AUTOSAR XML (schema 00049)
package /MICROSAR/Dem_swc/DataTypes
  26 x impl type:
    Dem_EventIdType: range raw 1..65535, implementation-data-type=uint16
    Dem_RatioIdType: range raw 1..65535, implementation-data-type=uint16
    Dem_DTCStatusMaskType: range raw 0..255, implementation-data-type=uint8
    Dem_OperationCycleIdType: range raw 0..255, implementation-data-type=uint8
    Dem_DTCGroupType: range raw 0..16777215, implementation-data-type=uint32
    Dem_DebouncingStateType:
      compu {mask 1: 1=DEM_TEMPORARILY_DEFECTIVE (Bit 0: Temporarily Defective (corresponds to 0 < FDC < 127)), mask 2: 2=DEM_FINALLY_DEFECTIVE (Bit 1: Finally Defective (corresponds to FDC = 127)), mask 4: 4=DEM_TEMPORARILY_HEALED (Bit 2: Temporarily healed (corresponds to -128 < FDC < 0)), mask 8: 8=DEM_TEST_COMPLETE (Bit 3: Test complete (corresponds to FDC = -128 or FDC = 127)), mask 16: 16=DEM_DTR_UPDATE (Bit 4: DTR Update (= Test complete && Debouncing complete && enable conditions / storage conditions fulfilled))}
      range raw 0..255
      implementation-data-type=uint8
    Dem_UdsStatusByteType:
      compu {mask 1: 1=DEM_UDS_STATUS_TF (bit 0: TestFailed), mask 2: 2=DEM_UDS_STATUS_TFTOC (bit 1: TestFailedThisOperationCycle), mask 4: 4=DEM_UDS_STATUS_PDTC (bit 2: PendingDTC), mask 8: 8=DEM_UDS_STATUS_CDTC (bit 3: ConfirmedDTC), mask 16: 16=DEM_UDS_STATUS_TNCSLC (bit 4: TestNotCompletedSinceLastClear), mask 32: 32=DEM_UDS_STATUS_TFSLC (bit 5: TestFailedSinceLastClear), mask 64: 64=DEM_UDS_STATUS_TNCTOC (bit 6: TestNotCompletedThisOperationCycle), mask 128: 128=DEM_UDS_STATUS_WIR (bit 7: WarningIndicatorRequested)}
      range raw 0..255
      implementation-data-type=uint8
    Dem_DTCSeverityType:
      compu {mask 255: 0=DEM_SEVERITY_NO_SEVERITY (DTC_NO_SEVERITY) (No severity information available), mask 31: 1=DEM_SEVERITY_WWHOBD_CLASS_NO_CLASS (DTC_CLASS) (No class information), mask 31: 2=DEM_SEVERITY_WWHOBD_CLASS_A (DTC_CLASS) (WWH-OBD Class A), mask 31: 4=DEM_SEVERITY_WWHOBD_CLASS_B1 (DTC_CLASS) (WWH-OBD Class B1), mask 31: 8=DEM_SEVERITY_WWHOBD_CLASS_B2 (DTC_CLASS) (WWH-OBD Class B2), mask 31: 16=DEM_SEVERITY_WWHOBD_CLASS_C (DTC_CLASS) (WWH-OBD Class C), mask 224: 32=DEM_SEVERITY_MAINTENANCE_ONLY (DTC_SEVERITY) (Maintenance required), mask 224: 64=DEM_SEVERITY_CHECK_AT_NEXT_HALT (DTC_SEVERITY) (Check at next halt), mask 224: 128=DEM_SEVERITY_CHECK_IMMEDIATELY (DTC_SEVERITY) (Check immediately)}
      range raw 0..255
      implementation-data-type=uint8
    Dem_MonitorStatusType: compu {mask 1: 1=DEM_MONITOR_STATUS_TF (bit 0: TestFailed), mask 2: 2=DEM_MONITOR_STATUS_TNCTOC (bit 1: TestNotCompletedThisOperationCycle)}, range raw 0..255, implementation-data-type=uint8
    Dem_EventStatusType:
      compu {0=DEM_EVENT_STATUS_PASSED, 1=DEM_EVENT_STATUS_FAILED, 2=DEM_EVENT_STATUS_PREPASSED, 3=DEM_EVENT_STATUS_PREFAILED, 4=DEM_EVENT_STATUS_FDC_THRESHOLD_REACHED, 5=DEM_EVENT_STATUS_PASSED_CONDITIONS_NOT_FULFILLED, 6=DEM_EVENT_STATUS_FAILED_CONDITIONS_NOT_FULFILLED, 7=DEM_EVENT_STATUS_PREPASSED_CONDITIONS_NOT_FULFILLED, 8=DEM_EVENT_STATUS_PREFAILED_CONDITIONS_NOT_FULFILLED}
      range raw 0..255
      implementation-data-type=uint8
    Dem_DTCKindType: compu {1=DEM_DTC_KIND_ALL_DTCS, 2=DEM_DTC_KIND_EMISSION_REL_DTCS}, range raw 0..255, implementation-data-type=uint8
    Dem_IumprDenomCondStatusType: compu {0=DEM_IUMPR_DEN_STATUS_NOT_REACHED, 1=DEM_IUMPR_DEN_STATUS_REACHED, 2=DEM_IUMPR_DEN_STATUS_INHIBITED}, range raw 0..255, implementation-data-type=uint8
    Dem_DebounceResetStatusType: compu {0=DEM_DEBOUNCE_STATUS_FREEZE, 1=DEM_DEBOUNCE_STATUS_RESET}, range raw 0..255, implementation-data-type=uint8
    Dem_DTRControlType: compu {0=DEM_DTR_CTL_NORMAL, 1=DEM_DTR_CTL_NO_MAX, 2=DEM_DTR_CTL_NO_MIN, 3=DEM_DTR_CTL_RESET, 4=DEM_DTR_CTL_INVISIBLE}, range raw 0..255, implementation-data-type=uint8
    Dem_IumprReadinessGroupType:
      compu {0=DEM_IUMPR_BOOSTPRS, 1=DEM_IUMPR_CAT1, 2=DEM_IUMPR_CAT2, 3=DEM_IUMPR_EGR, 4=DEM_IUMPR_EGSENSOR, 5=DEM_IUMPR_EVAP, 6=DEM_IUMPR_NMHCCAT, 7=DEM_IUMPR_NOXADSORB, 8=DEM_IUMPR_NOXCAT, 9=DEM_IUMPR_OXS1, 10=DEM_IUMPR_OXS2, 11=DEM_IUMPR_PMFILTER, 12=DEM_IUMPR_PRIVATE, 13=DEM_IUMPR_SAIR, 14=DEM_IUMPR_SECOXS1, 15=DEM_IUMPR_SECOXS2, 16=DEM_IUMPR_FLSYS, 17=DEM_IUMPR_AFRI1, 18=DEM_IUMPR_AFRI2, 19=DEM_IUMPR_PF1, 20=DEM_IUMPR_PF2, 255=DEM_IUMPR_ALLGROUPS}
      range raw 0..255
      implementation-data-type=uint8
    Dem_IumprDenomCondIdType: compu {1=DEM_IUMPR_GENERAL_DENOMINATOR, 2=DEM_IUMPR_DEN_COND_COLDSTART, 3=DEM_IUMPR_DEN_COND_EVAP, 4=DEM_IUMPR_DEN_COND_500MI, 5=DEM_IUMPR_GENERAL_INDIVIDUAL_DENOMINATOR, 6=DEM_IUMPR_GENERAL_OBDCOND, 7=DEM_IUMPR_DEN_COND_INDEPENDENT}, range raw 0..255, implementation-data-type=uint8
    Dem_InitMonitorReasonType: compu {1=DEM_INIT_MONITOR_CLEAR, 2=DEM_INIT_MONITOR_RESTART, 3=DEM_INIT_MONITOR_REENABLED, 4=DEM_INIT_MONITOR_STORAGE_REENABLED}, range raw 1..4, implementation-data-type=uint8
    Dem_OperationCycleStateType: compu {0=DEM_CYCLE_STATE_START, 1=DEM_CYCLE_STATE_END}, range raw 0..1, implementation-data-type=uint8
    Dem_IndicatorStatusType: compu {0=DEM_INDICATOR_OFF, 1=DEM_INDICATOR_CONTINUOUS, 2=DEM_INDICATOR_BLINKING, 3=DEM_INDICATOR_BLINK_CONT, 4=DEM_INDICATOR_SLOW_FLASH, 5=DEM_INDICATOR_FAST_FLASH, 6=DEM_INDICATOR_ON_DEMAND, 7=DEM_INDICATOR_SHORT}, range raw 0..7, implementation-data-type=uint8
    Dem_DTCOriginType: compu {1=DEM_DTC_ORIGIN_PRIMARY_MEMORY, 2=DEM_DTC_ORIGIN_MIRROR_MEMORY, 3=DEM_DTC_ORIGIN_PERMANENT_MEMORY, 4=DEM_DTC_ORIGIN_OBD_RELEVANT_MEMORY, 256=DEM_DTC_ORIGIN_SECONDARY_MEMORY}, range raw 1..511, implementation-data-type=uint16
    Dem_BufferLengthType: range raw 1..65535, implementation-data-type=uint16
    Dcm_NegativeResponseCodeType: range raw 1..255, implementation-data-type=uint8
    Dem_DTCFormatType: compu {0=DEM_DTC_FORMAT_OBD, 1=DEM_DTC_FORMAT_UDS, 2=DEM_DTC_FORMAT_J1939, 3=DEM_DTC_FORMAT_OBD_3BYTE}, range raw 0..3, implementation-data-type=uint8
    Dem_MaxDataValueType: category=ARRAY, sw-calibration-access=READ-ONLY
      element Dem_MaxDataValueTypeElement: array-size=6, array-size-semantics=FIXED-SIZE, implementation-data-type=uint8
    DataPrimitiveType_uint16: implementation-data-type=uint16
    DataArrayType_uint8_6: category=ARRAY, sw-calibration-access=READ-ONLY
      element DataArrayType_uint8_6Element: array-size=6, array-size-semantics=FIXED-SIZE, implementation-data-type=uint8
package /MICROSAR/Dem_swc/Interfaces
  12 x client server interface, all with is-service=true, service-kind=DIAGNOSTIC-EVENT-MANAGER:
    DemServices
      operation GetPostRunRequested: possible-error=DemServices/E_NOT_OK
        arg IsRequested: type=boolean, direction=OUT
      operation GetDTCStatusAvailabilityMask: possible-error=DemServices/E_NOT_OK
        arg ClientId: type=uint8, direction=IN
        arg DTCStatusMask: type=uint8, direction=OUT
      error E_NOT_OK: error-code=1
    EvMemOverflowIndication
      operation GetEventMemoryOverflow: possible-error=EvMemOverflowIndication/E_NOT_OK
        arg OverflowIndication: type=boolean, direction=OUT
      operation GetNumberOfEventMemoryEntries: possible-error=EvMemOverflowIndication/E_NOT_OK
        arg NumberOfEventMemoryEntries: type=uint8, direction=OUT
      error E_NOT_OK: error-code=1
    GeneralDiagnosticInfo
      11 x operation:
        GetEventStatus: possible-error=GeneralDiagnosticInfo/E_NOT_OK
          arg EventId: type=Dem_EventIdType, direction=IN
          arg UDSStatusByte: type=Dem_UdsStatusByteType, direction=OUT
        GetEventFailed: possible-error=GeneralDiagnosticInfo/E_NOT_OK
          arg EventId: type=Dem_EventIdType, direction=IN
          arg EventFailed: type=boolean, direction=OUT
        GetEventTested: possible-error=GeneralDiagnosticInfo/E_NOT_OK
          arg EventId: type=Dem_EventIdType, direction=IN
          arg EventTested: type=boolean, direction=OUT
        GetDTCOfEvent: possible-error=[GeneralDiagnosticInfo/E_NOT_OK, GeneralDiagnosticInfo/DEM_E_NO_DTC_AVAILABLE]
          arg EventId: type=Dem_EventIdType, direction=IN
          arg DTCFormat: type=Dem_DTCFormatType, direction=IN
          arg DTCOfEvent: type=uint32, direction=OUT
        GetFaultDetectionCounter: possible-error=[GeneralDiagnosticInfo/E_NOT_OK, GeneralDiagnosticInfo/DEM_E_NO_FDC_AVAILABLE]
          arg EventId: type=Dem_EventIdType, direction=IN
          arg FaultDetectionCounter: type=sint8, direction=OUT
        GetEventEnableCondition: possible-error=GeneralDiagnosticInfo/E_NOT_OK
          arg EventId: type=Dem_EventIdType, direction=IN
          arg ConditionFullfilled: type=boolean, direction=OUT
        GetDebouncingOfEvent: possible-error=GeneralDiagnosticInfo/E_NOT_OK
          arg EventId: type=Dem_EventIdType, direction=IN
          arg DebouncingState: type=Dem_DebouncingStateType, direction=OUT
        GetEventUdsStatus: possible-error=GeneralDiagnosticInfo/E_NOT_OK
          arg EventId: type=Dem_EventIdType, direction=IN
          arg UDSStatusByte: type=Dem_UdsStatusByteType, direction=OUT
        GetEventFreezeFrameDataEx: possible-error=[GeneralDiagnosticInfo/E_NOT_OK, GeneralDiagnosticInfo/DEM_BUFFER_TOO_SMALL, GeneralDiagnosticInfo/DEM_NO_SUCH_ELEMENT]
          5 x arg:
            EventId: type=Dem_EventIdType, direction=IN
            RecordNumber: type=uint8, direction=IN
            DataId: type=uint16, direction=IN
            DestBuffer: type=Dem_MaxDataValueType, direction=OUT
            BufSize: type=uint16, direction=INOUT
        GetEventExtendedDataRecordEx: possible-error=[GeneralDiagnosticInfo/E_NOT_OK, GeneralDiagnosticInfo/DEM_BUFFER_TOO_SMALL, GeneralDiagnosticInfo/DEM_NO_SUCH_ELEMENT]
          4 x arg:
            EventId: type=Dem_EventIdType, direction=IN
            RecordNumber: type=uint8, direction=IN
            DestBuffer: type=Dem_MaxDataValueType, direction=OUT
            BufSize: type=uint16, direction=INOUT
        GetMonitorStatus: possible-error=GeneralDiagnosticInfo/E_NOT_OK
          arg EventId: type=Dem_EventIdType, direction=IN
          arg MonitorStatus: type=Dem_MonitorStatusType, direction=OUT
      5 x error:
        E_NOT_OK: error-code=1
        DEM_E_NO_DTC_AVAILABLE: error-code=10
        DEM_E_NO_FDC_AVAILABLE: error-code=14
        DEM_BUFFER_TOO_SMALL: error-code=21
        DEM_NO_SUCH_ELEMENT: error-code=48
    DiagnosticInfo
      11 x operation:
        GetEventStatus: possible-error=DiagnosticInfo/E_NOT_OK
          arg UDSStatusByte: type=Dem_UdsStatusByteType, direction=OUT
        GetEventFailed: possible-error=DiagnosticInfo/E_NOT_OK
          arg EventFailed: type=boolean, direction=OUT
        GetEventTested: possible-error=DiagnosticInfo/E_NOT_OK
          arg EventTested: type=boolean, direction=OUT
        GetDTCOfEvent: possible-error=[DiagnosticInfo/E_NOT_OK, DiagnosticInfo/DEM_E_NO_DTC_AVAILABLE]
          arg DTCFormat: type=Dem_DTCFormatType, direction=IN
          arg DTCOfEvent: type=uint32, direction=OUT
        GetFaultDetectionCounter: possible-error=[DiagnosticInfo/E_NOT_OK, DiagnosticInfo/DEM_E_NO_FDC_AVAILABLE]
          arg FaultDetectionCounter: type=sint8, direction=OUT
        GetEventEnableCondition: possible-error=DiagnosticInfo/E_NOT_OK
          arg ConditionFullfilled: type=boolean, direction=OUT
        GetDebouncingOfEvent: possible-error=DiagnosticInfo/E_NOT_OK
          arg DebouncingState: type=Dem_DebouncingStateType, direction=OUT
        GetEventUdsStatus: possible-error=DiagnosticInfo/E_NOT_OK
          arg UDSStatusByte: type=Dem_UdsStatusByteType, direction=OUT
        GetEventFreezeFrameDataEx: possible-error=[DiagnosticInfo/E_NOT_OK, DiagnosticInfo/DEM_BUFFER_TOO_SMALL, DiagnosticInfo/DEM_NO_SUCH_ELEMENT]
          4 x arg:
            RecordNumber: type=uint8, direction=IN
            DataId: type=uint16, direction=IN
            DestBuffer: type=Dem_MaxDataValueType, direction=OUT
            BufSize: type=uint16, direction=INOUT
        GetEventExtendedDataRecordEx: possible-error=[DiagnosticInfo/E_NOT_OK, DiagnosticInfo/DEM_BUFFER_TOO_SMALL, DiagnosticInfo/DEM_NO_SUCH_ELEMENT]
          arg RecordNumber: type=uint8, direction=IN
          arg DestBuffer: type=Dem_MaxDataValueType, direction=OUT
          arg BufSize: type=uint16, direction=INOUT
        GetMonitorStatus: possible-error=DiagnosticInfo/E_NOT_OK
          arg MonitorStatus: type=Dem_MonitorStatusType, direction=OUT
      5 x error:
        E_NOT_OK: error-code=1
        DEM_E_NO_DTC_AVAILABLE: error-code=10
        DEM_E_NO_FDC_AVAILABLE: error-code=14
        DEM_BUFFER_TOO_SMALL: error-code=21
        DEM_NO_SUCH_ELEMENT: error-code=48
    OperationCycle
      operation SetOperationCycleState: possible-error=[OperationCycle/E_OK, OperationCycle/E_NOT_OK]
        arg CycleState: type=Dem_OperationCycleStateType, direction=IN
      operation GetOperationCycleState: possible-error=[OperationCycle/E_OK, OperationCycle/E_NOT_OK]
        arg CycleState: type=Dem_OperationCycleStateType, direction=OUT
      error E_NOT_OK: error-code=1
      error E_OK: error-code=0
    ClearDTC
      operation ClearDTC: possible-error=[ClearDTC/E_NOT_OK, DEM_CLEAR_FAILED, DEM_PENDING, DEM_CLEAR_BUSY, DEM_CLEAR_MEMORY_ERROR, DEM_WRONG_DTC, DEM_WRONG_DTCORIGIN]
      operation SelectDTC: possible-error=[ClearDTC/E_OK, ClearDTC/E_NOT_OK, DEM_BUSY]
        arg DTC: type=uint32, direction=IN
        arg DTCFormat: type=Dem_DTCFormatType, direction=IN
        arg DTCOrigin: type=Dem_DTCOriginType, direction=IN
      9 x error:
        E_OK: error-code=0
        E_NOT_OK: error-code=1
        DEM_CLEAR_FAILED: error-code=7
        DEM_PENDING: error-code=4
        DEM_CLEAR_BUSY: error-code=5
        DEM_CLEAR_MEMORY_ERROR: error-code=6
        DEM_WRONG_DTC: error-code=8
        DEM_WRONG_DTCORIGIN: error-code=9
        DEM_BUSY: error-code=22
    DiagnosticMonitor
      11 x operation:
        SetEventStatus: possible-error=DiagnosticMonitor/E_NOT_OK
          arg EventStatus: type=Dem_EventStatusType, direction=IN
        ResetEventStatus: possible-error=DiagnosticMonitor/E_NOT_OK
        ResetEventDebounceStatus: possible-error=DiagnosticMonitor/E_NOT_OK
          arg DebounceResetStatus: type=Dem_DebounceResetStatusType, direction=IN
        GetEventUdsStatus: possible-error=DiagnosticMonitor/E_NOT_OK
          arg UDSStatusByte: type=Dem_UdsStatusByteType, direction=OUT
        GetEventStatus: possible-error=DiagnosticMonitor/E_NOT_OK
          arg UDSStatusByte: type=Dem_UdsStatusByteType, direction=OUT
        GetEventFailed: possible-error=DiagnosticMonitor/E_NOT_OK
          arg EventFailed: type=boolean, direction=OUT
        GetEventTested: possible-error=DiagnosticMonitor/E_NOT_OK
          arg EventTested: type=boolean, direction=OUT
        GetDTCOfEvent: possible-error=[DiagnosticMonitor/E_NOT_OK, DiagnosticMonitor/DEM_E_NO_DTC_AVAILABLE]
          arg DTCFormat: type=Dem_DTCFormatType, direction=IN
          arg DTCOfEvent: type=uint32, direction=OUT
        GetFaultDetectionCounter: possible-error=[DiagnosticMonitor/E_NOT_OK, DiagnosticMonitor/DEM_E_NO_FDC_AVAILABLE]
          arg FaultDetectionCounter: type=sint8, direction=OUT
        GetEventFreezeFrameDataEx: possible-error=[DiagnosticMonitor/E_NOT_OK, DiagnosticMonitor/DEM_BUFFER_TOO_SMALL, DiagnosticMonitor/DEM_NO_SUCH_ELEMENT]
          4 x arg:
            RecordNumber: type=uint8, direction=IN
            DataId: type=uint16, direction=IN
            DestBuffer: type=Dem_MaxDataValueType, direction=OUT
            BufSize: type=uint16, direction=INOUT
        GetEventExtendedDataRecordEx: possible-error=[DiagnosticMonitor/E_NOT_OK, DiagnosticMonitor/DEM_BUFFER_TOO_SMALL, DiagnosticMonitor/DEM_NO_SUCH_ELEMENT]
          arg RecordNumber: type=uint8, direction=IN
          arg DestBuffer: type=Dem_MaxDataValueType, direction=OUT
          arg BufSize: type=uint16, direction=INOUT
      5 x error:
        E_NOT_OK: error-code=1
        DEM_E_NO_DTC_AVAILABLE: error-code=10
        DEM_E_NO_FDC_AVAILABLE: error-code=14
        DEM_BUFFER_TOO_SMALL: error-code=21
        DEM_NO_SUCH_ELEMENT: error-code=48
    IndicatorStatus
      operation GetIndicatorStatus: possible-error=IndicatorStatus/E_NOT_OK
        arg IndicatorStatus: type=Dem_IndicatorStatusType, direction=OUT
      error E_NOT_OK: error-code=1
    CSDataServices_PID_0x12_DID_Data
      operation ReadData: possible-error=CSDataServices_PID_0x12_DID_Data/E_NOT_OK
        arg Data: type=DataPrimitiveType_uint16, direction=OUT
      error E_NOT_OK: error-code=1
    CSDataServices_DID_0x1_DID_Data_GlobalTime
      operation ReadData: possible-error=CSDataServices_DID_0x1_DID_Data_GlobalTime/E_NOT_OK
        arg Data: type=DataArrayType_uint8_6, direction=OUT
      error E_NOT_OK: error-code=1
    CSDataServices_PID_0x13_DID_Data
      operation ReadData: possible-error=CSDataServices_PID_0x13_DID_Data/E_NOT_OK
        arg Data: type=DataPrimitiveType_uint16, direction=OUT
      error E_NOT_OK: error-code=1
    EventAvailable
      operation SetEventAvailable: possible-error=[EventAvailable/E_OK, EventAvailable/E_NOT_OK]
        arg AvailableStatus: type=boolean, direction=IN
      operation GetEventAvailable: possible-error=[EventAvailable/E_OK, EventAvailable/E_NOT_OK]
        arg AvailableStatus: type=boolean, direction=OUT
      error E_OK: error-code=0
      error E_NOT_OK: error-code=1
package /MICROSAR/Dem_swc/ComponentTypes
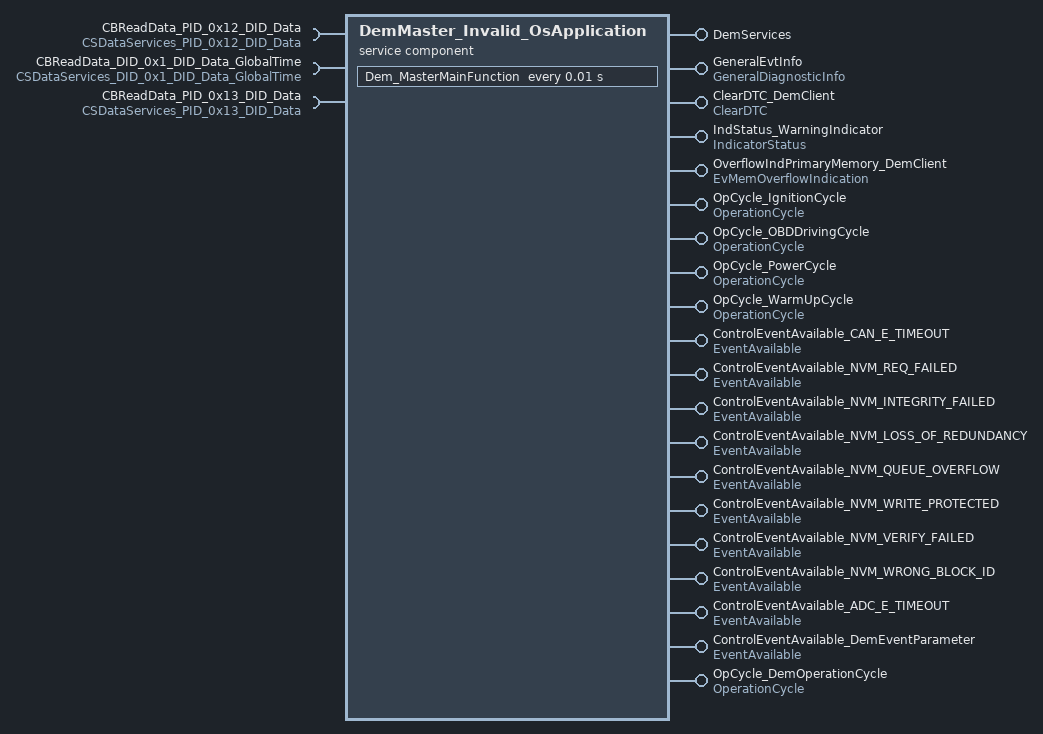
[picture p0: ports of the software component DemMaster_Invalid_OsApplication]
  service sw component type DemMaster_Invalid_OsApplication: category=SERVICE_COMPONENT
    9 x provide port:
      DemServices: provided-interface=DemServices
      GeneralEvtInfo: provided-interface=GeneralDiagnosticInfo
      ClearDTC_DemClient: provided-interface=ClearDTC
      IndStatus_WarningIndicator: provided-interface=IndicatorStatus
      OverflowIndPrimaryMemory_DemClient: provided-interface=EvMemOverflowIndication
      OpCycle_IgnitionCycle: provided-interface=OperationCycle
      OpCycle_OBDDrivingCycle: provided-interface=OperationCycle
      OpCycle_PowerCycle: provided-interface=OperationCycle
      OpCycle_WarmUpCycle: provided-interface=OperationCycle
    require port CBReadData_PID_0x12_DID_Data: required-interface=CSDataServices_PID_0x12_DID_Data
    require port CBReadData_DID_0x1_DID_Data_GlobalTime: required-interface=CSDataServices_DID_0x1_DID_Data_GlobalTime
    require port CBReadData_PID_0x13_DID_Data: required-interface=CSDataServices_PID_0x13_DID_Data
    11 x provide port:
      ControlEventAvailable_CAN_E_TIMEOUT: provided-interface=EventAvailable
      ControlEventAvailable_NVM_REQ_FAILED: provided-interface=EventAvailable
      ControlEventAvailable_NVM_INTEGRITY_FAILED: provided-interface=EventAvailable
      ControlEventAvailable_NVM_LOSS_OF_REDUNDANCY: provided-interface=EventAvailable
      ControlEventAvailable_NVM_QUEUE_OVERFLOW: provided-interface=EventAvailable
      ControlEventAvailable_NVM_WRITE_PROTECTED: provided-interface=EventAvailable
      ControlEventAvailable_NVM_VERIFY_FAILED: provided-interface=EventAvailable
      ControlEventAvailable_NVM_WRONG_BLOCK_ID: provided-interface=EventAvailable
      ControlEventAvailable_ADC_E_TIMEOUT: provided-interface=EventAvailable
      ControlEventAvailable_DemEventParameter: provided-interface=EventAvailable
      OpCycle_DemOperationCycle: provided-interface=OperationCycle
    behavior DemMaster_Invalid_OsApplicationInternalBehavior: handle-termination-and-restart=NO-SUPPORT, included-data-type-set=data-type=[Dem_EventIdType, Dem_BufferLengthType, Dcm_NegativeResponseCodeType, Dem_RatioIdType, Dem_EventStatusType, Dem_UdsStatusByteType, Dem_DTCFormatType, Dem_InitMonitorReasonType, Dem_OperationCycleStateType, Dem_DTCStatusMaskType, Dem_IndicatorStatusType, Dem_MaxDataValueType, Dem_DTCKindType, Dem_DTCGroupType, Dem_IumprDenomCondIdType, Dem_IumprDenomCondStatusType, Dem_DebounceResetStatusType, Dem_DebouncingStateType, Dem_IumprReadinessGroupType, Dem_DTRControlType, Dem_DTCSeverityType, Dem_MonitorStatusType]
      timing event Timer_Dem_MasterMainFunction: start-on-event=Dem_MasterMainFunction, period=0.01
      48 x operation invoked event:
        OpEventPostRunRequested_GetPostRunRequested_DemServices: start-on-event=PostRunRequested, operation=DemServices.GetPostRunRequested
        OpEventGetDTCStatusAvailabilityMask_GetDTCStatusAvailabilityMask_DemServices: start-on-event=GetDTCStatusAvailabilityMask, operation=DemServices.GetDTCStatusAvailabilityMask
        OpEventGetEventUdsStatus_GetEventUdsStatus_GeneralEvtInfo: start-on-event=DemMaster_Invalid_OsApplicationInternalBehavior/GetEventUdsStatus, operation=GeneralEvtInfo.GetEventUdsStatus
        OpEventGetEventStatus_GetEventStatus_GeneralEvtInfo: start-on-event=DemMaster_Invalid_OsApplicationInternalBehavior/GetEventStatus, operation=GeneralEvtInfo.GetEventStatus
        OpEventGetEventFailed_GetEventFailed_GeneralEvtInfo: start-on-event=DemMaster_Invalid_OsApplicationInternalBehavior/GetEventFailed, operation=GeneralEvtInfo.GetEventFailed
        OpEventGetEventTested_GetEventTested_GeneralEvtInfo: start-on-event=DemMaster_Invalid_OsApplicationInternalBehavior/GetEventTested, operation=GeneralEvtInfo.GetEventTested
        OpEventGetDTCOfEvent_GetDTCOfEvent_GeneralEvtInfo: start-on-event=DemMaster_Invalid_OsApplicationInternalBehavior/GetDTCOfEvent, operation=GeneralEvtInfo.GetDTCOfEvent
        OpEventGetFaultDetectionCounter_GetFaultDetectionCounter_GeneralEvtInfo: start-on-event=DemMaster_Invalid_OsApplicationInternalBehavior/GetFaultDetectionCounter, operation=GeneralEvtInfo.GetFaultDetectionCounter
        OpEventGetEventFreezeFrameDataEx_GetEventFreezeFrameDataEx_GeneralEvtInfo: start-on-event=DemMaster_Invalid_OsApplicationInternalBehavior/GetEventFreezeFrameDataEx, operation=GeneralEvtInfo.GetEventFreezeFrameDataEx
        OpEventGetEventExtendedDataRecordEx_GetEventExtendedDataRecordEx_GeneralEvtInfo: start-on-event=DemMaster_Invalid_OsApplicationInternalBehavior/GetEventExtendedDataRecordEx, operation=GeneralEvtInfo.GetEventExtendedDataRecordEx
        OpEventGetEventEnableCondition_GetEventEnableCondition_GeneralEvtInfo: start-on-event=DemMaster_Invalid_OsApplicationInternalBehavior/GetEventEnableCondition, operation=GeneralEvtInfo.GetEventEnableCondition
        OpEventGetDebouncingOfEvent_GetDebouncingOfEvent_GeneralEvtInfo: start-on-event=DemMaster_Invalid_OsApplicationInternalBehavior/GetDebouncingOfEvent, operation=GeneralEvtInfo.GetDebouncingOfEvent
        OpEventGetMonitorStatus_GetMonitorStatus_GeneralEvtInfo: start-on-event=DemMaster_Invalid_OsApplicationInternalBehavior/GetMonitorStatus, operation=GeneralEvtInfo.GetMonitorStatus
        OpEventClearDTC_ClearDTC_ClearDTC_DemClient: start-on-event=ClearDTC, operation=ClearDTC_DemClient.ClearDTC
        OpEventSelectDTC_SelectDTC_ClearDTC_DemClient: start-on-event=SelectDTC, operation=ClearDTC_DemClient.SelectDTC
        OpEventGetIndicatorStatus_GetIndicatorStatus_IndStatus_WarningIndicator: start-on-event=GetIndicatorStatus, operation=IndStatus_WarningIndicator.GetIndicatorStatus
        OpEventGetEventMemoryOverflow_GetEventMemoryOverflow_OverflowIndPrimaryMemory_DemClient: start-on-event=GetEventMemoryOverflow, operation=OverflowIndPrimaryMemory_DemClient.GetEventMemoryOverflow
        OpEventGetNumberOfEventMemoryEntries_GetNumberOfEventMemoryEntries_OverflowIndPrimaryMemory_DemClient: start-on-event=GetNumberOfEventMemoryEntries, operation=OverflowIndPrimaryMemory_DemClient.GetNumberOfEventMemoryEntries
        OpEventGetOperationCycleState_GetOperationCycleState_OpCycle_IgnitionCycle: start-on-event=GetOperationCycleState, operation=OpCycle_IgnitionCycle.GetOperationCycleState
        OpEventGetOperationCycleState_GetOperationCycleState_OpCycle_OBDDrivingCycle: start-on-event=GetOperationCycleState, operation=OpCycle_OBDDrivingCycle.GetOperationCycleState
        OpEventGetOperationCycleState_GetOperationCycleState_OpCycle_PowerCycle: start-on-event=GetOperationCycleState, operation=OpCycle_PowerCycle.GetOperationCycleState
        OpEventGetOperationCycleState_GetOperationCycleState_OpCycle_WarmUpCycle: start-on-event=GetOperationCycleState, operation=OpCycle_WarmUpCycle.GetOperationCycleState
        OpEventSetOperationCycleState_SetOperationCycleState_OpCycle_IgnitionCycle: start-on-event=SetOperationCycleState, operation=OpCycle_IgnitionCycle.SetOperationCycleState
        OpEventSetOperationCycleState_SetOperationCycleState_OpCycle_OBDDrivingCycle: start-on-event=SetOperationCycleState, operation=OpCycle_OBDDrivingCycle.SetOperationCycleState
        OpEventSetOperationCycleState_SetOperationCycleState_OpCycle_PowerCycle: start-on-event=SetOperationCycleState, operation=OpCycle_PowerCycle.SetOperationCycleState
        OpEventSetOperationCycleState_SetOperationCycleState_OpCycle_WarmUpCycle: start-on-event=SetOperationCycleState, operation=OpCycle_WarmUpCycle.SetOperationCycleState
        OpEventSetEventAvailable_SetEventAvailable_ControlEventAvailable_CAN_E_TIMEOUT: start-on-event=SetEventAvailable, operation=ControlEventAvailable_CAN_E_TIMEOUT.SetEventAvailable
        OpEventSetEventAvailable_SetEventAvailable_ControlEventAvailable_NVM_REQ_FAILED: start-on-event=SetEventAvailable, operation=ControlEventAvailable_NVM_REQ_FAILED.SetEventAvailable
        OpEventSetEventAvailable_SetEventAvailable_ControlEventAvailable_NVM_INTEGRITY_FAILED: start-on-event=SetEventAvailable, operation=ControlEventAvailable_NVM_INTEGRITY_FAILED.SetEventAvailable
        OpEventSetEventAvailable_SetEventAvailable_ControlEventAvailable_NVM_LOSS_OF_REDUNDANCY: start-on-event=SetEventAvailable, operation=ControlEventAvailable_NVM_LOSS_OF_REDUNDANCY.SetEventAvailable
        OpEventSetEventAvailable_SetEventAvailable_ControlEventAvailable_NVM_QUEUE_OVERFLOW: start-on-event=SetEventAvailable, operation=ControlEventAvailable_NVM_QUEUE_OVERFLOW.SetEventAvailable
        OpEventSetEventAvailable_SetEventAvailable_ControlEventAvailable_NVM_WRITE_PROTECTED: start-on-event=SetEventAvailable, operation=ControlEventAvailable_NVM_WRITE_PROTECTED.SetEventAvailable
        OpEventSetEventAvailable_SetEventAvailable_ControlEventAvailable_NVM_VERIFY_FAILED: start-on-event=SetEventAvailable, operation=ControlEventAvailable_NVM_VERIFY_FAILED.SetEventAvailable
        OpEventSetEventAvailable_SetEventAvailable_ControlEventAvailable_NVM_WRONG_BLOCK_ID: start-on-event=SetEventAvailable, operation=ControlEventAvailable_NVM_WRONG_BLOCK_ID.SetEventAvailable
        OpEventSetEventAvailable_SetEventAvailable_ControlEventAvailable_ADC_E_TIMEOUT: start-on-event=SetEventAvailable, operation=ControlEventAvailable_ADC_E_TIMEOUT.SetEventAvailable
        OpEventSetEventAvailable_SetEventAvailable_ControlEventAvailable_DemEventParameter: start-on-event=SetEventAvailable, operation=ControlEventAvailable_DemEventParameter.SetEventAvailable
        OpEventGetEventAvailable_GetEventAvailable_ControlEventAvailable_CAN_E_TIMEOUT: start-on-event=GetEventAvailable, operation=ControlEventAvailable_CAN_E_TIMEOUT.GetEventAvailable
        OpEventGetEventAvailable_GetEventAvailable_ControlEventAvailable_NVM_REQ_FAILED: start-on-event=GetEventAvailable, operation=ControlEventAvailable_NVM_REQ_FAILED.GetEventAvailable
        OpEventGetEventAvailable_GetEventAvailable_ControlEventAvailable_NVM_INTEGRITY_FAILED: start-on-event=GetEventAvailable, operation=ControlEventAvailable_NVM_INTEGRITY_FAILED.GetEventAvailable
        OpEventGetEventAvailable_GetEventAvailable_ControlEventAvailable_NVM_LOSS_OF_REDUNDANCY: start-on-event=GetEventAvailable, operation=ControlEventAvailable_NVM_LOSS_OF_REDUNDANCY.GetEventAvailable
        OpEventGetEventAvailable_GetEventAvailable_ControlEventAvailable_NVM_QUEUE_OVERFLOW: start-on-event=GetEventAvailable, operation=ControlEventAvailable_NVM_QUEUE_OVERFLOW.GetEventAvailable
        OpEventGetEventAvailable_GetEventAvailable_ControlEventAvailable_NVM_WRITE_PROTECTED: start-on-event=GetEventAvailable, operation=ControlEventAvailable_NVM_WRITE_PROTECTED.GetEventAvailable
        OpEventGetEventAvailable_GetEventAvailable_ControlEventAvailable_NVM_VERIFY_FAILED: start-on-event=GetEventAvailable, operation=ControlEventAvailable_NVM_VERIFY_FAILED.GetEventAvailable
        OpEventGetEventAvailable_GetEventAvailable_ControlEventAvailable_NVM_WRONG_BLOCK_ID: start-on-event=GetEventAvailable, operation=ControlEventAvailable_NVM_WRONG_BLOCK_ID.GetEventAvailable
        OpEventGetEventAvailable_GetEventAvailable_ControlEventAvailable_ADC_E_TIMEOUT: start-on-event=GetEventAvailable, operation=ControlEventAvailable_ADC_E_TIMEOUT.GetEventAvailable
        OpEventGetEventAvailable_GetEventAvailable_ControlEventAvailable_DemEventParameter: start-on-event=GetEventAvailable, operation=ControlEventAvailable_DemEventParameter.GetEventAvailable
        OpEventGetOperationCycleState_GetOperationCycleState_OpCycle_DemOperationCycle: start-on-event=GetOperationCycleState, operation=OpCycle_DemOperationCycle.GetOperationCycleState
        OpEventSetOperationCycleState_SetOperationCycleState_OpCycle_DemOperationCycle: start-on-event=SetOperationCycleState, operation=OpCycle_DemOperationCycle.SetOperationCycleState
      port-api-options:
        enable-take-address=true, indirect-api=false, port=DemServices
        enable-take-address=true, indirect-api=false, port=DemMaster_Invalid_OsApplication/GeneralEvtInfo
        {enable-take-address=true, indirect-api=false, port-defined-argument-value{value=0, value-type=uint8}, port=ClearDTC_DemClient}
        {enable-take-address=true, indirect-api=false, port-defined-argument-value{value=0, value-type=uint8}, port=IndStatus_WarningIndicator}
        {enable-take-address=true, indirect-api=false, port-arg-values=[{value=0, value-type=uint8}, {value=1, value-type=Dem_DTCOriginType}], port=OverflowIndPrimaryMemory_DemClient}
        enable-take-address=true, indirect-api=false, port=DemMaster_Invalid_OsApplication/CBReadData_PID_0x12_DID_Data
        enable-take-address=true, indirect-api=false, port=DemMaster_Invalid_OsApplication/CBReadData_DID_0x1_DID_Data_GlobalTime
        enable-take-address=true, indirect-api=false, port=DemMaster_Invalid_OsApplication/CBReadData_PID_0x13_DID_Data
        {enable-take-address=true, indirect-api=false, port-defined-argument-value{value=1, value-type=Dem_EventIdType}, port=ControlEventAvailable_CAN_E_TIMEOUT}
        {enable-take-address=true, indirect-api=false, port-defined-argument-value{value=5, value-type=Dem_EventIdType}, port=ControlEventAvailable_NVM_REQ_FAILED}
        {enable-take-address=true, indirect-api=false, port-defined-argument-value{value=2, value-type=Dem_EventIdType}, port=ControlEventAvailable_NVM_INTEGRITY_FAILED}
        {enable-take-address=true, indirect-api=false, port-defined-argument-value{value=3, value-type=Dem_EventIdType}, port=ControlEventAvailable_NVM_LOSS_OF_REDUNDANCY}
        {enable-take-address=true, indirect-api=false, port-defined-argument-value{value=4, value-type=Dem_EventIdType}, port=ControlEventAvailable_NVM_QUEUE_OVERFLOW}
        {enable-take-address=true, indirect-api=false, port-defined-argument-value{value=7, value-type=Dem_EventIdType}, port=ControlEventAvailable_NVM_WRITE_PROTECTED}
        {enable-take-address=true, indirect-api=false, port-defined-argument-value{value=6, value-type=Dem_EventIdType}, port=ControlEventAvailable_NVM_VERIFY_FAILED}
        {enable-take-address=true, indirect-api=false, port-defined-argument-value{value=8, value-type=Dem_EventIdType}, port=ControlEventAvailable_NVM_WRONG_BLOCK_ID}
        {enable-take-address=true, indirect-api=false, port-defined-argument-value{value=9, value-type=Dem_EventIdType}, port=ControlEventAvailable_ADC_E_TIMEOUT}
        {enable-take-address=true, indirect-api=false, port-defined-argument-value{value=10, value-type=Dem_EventIdType}, port=ControlEventAvailable_DemEventParameter}
        {enable-take-address=true, indirect-api=false, port-defined-argument-value{value=0, value-type=uint8}, port=OpCycle_DemOperationCycle}
        {enable-take-address=true, indirect-api=false, port-defined-argument-value{value=1, value-type=uint8}, port=OpCycle_IgnitionCycle}
        {enable-take-address=true, indirect-api=false, port-defined-argument-value{value=2, value-type=uint8}, port=OpCycle_OBDDrivingCycle}
        {enable-take-address=true, indirect-api=false, port-defined-argument-value{value=3, value-type=uint8}, port=OpCycle_PowerCycle}
        {enable-take-address=true, indirect-api=false, port-defined-argument-value{value=4, value-type=uint8}, port=OpCycle_WarmUpCycle}
      23 x runnable:
        Dem_MasterMainFunction
          sync call OpServerCallDem_MasterMainFunction_ReadData_CBReadData_PID_0x12_DID_Data: operation=CBReadData_PID_0x12_DID_Data.ReadData, timeout=0
          sync call OpServerCallDem_MasterMainFunction_ReadData_CBReadData_DID_0x1_DID_Data_GlobalTime: operation=CBReadData_DID_0x1_DID_Data_GlobalTime.ReadData, timeout=0
          sync call OpServerCallDem_MasterMainFunction_ReadData_CBReadData_PID_0x13_DID_Data: operation=CBReadData_PID_0x13_DID_Data.ReadData, timeout=0
        PostRunRequested: can-be-invoked-concurrently=true, symbol=Dem_PostRunRequested
        GetDTCStatusAvailabilityMask: can-be-invoked-concurrently=true, symbol=Dem_GetDTCStatusAvailabilityMask
        ClearDTC: can-be-invoked-concurrently=true, symbol=Dem_ClearDTC
        SelectDTC: can-be-invoked-concurrently=true, symbol=Dem_SelectDTC
        GetEventMemoryOverflow: can-be-invoked-concurrently=true, symbol=Dem_GetEventMemoryOverflow
        GetNumberOfEventMemoryEntries: can-be-invoked-concurrently=true, symbol=Dem_GetNumberOfEventMemoryEntries
        GetEventUdsStatus: can-be-invoked-concurrently=true, symbol=Dem_GetEventUdsStatus
        GetEventStatus: can-be-invoked-concurrently=true, symbol=Dem_GetEventUdsStatus
        GetEventFailed: can-be-invoked-concurrently=true, symbol=Dem_GetEventFailed
        GetEventTested: can-be-invoked-concurrently=true, symbol=Dem_GetEventTested
        GetDTCOfEvent: can-be-invoked-concurrently=true, symbol=Dem_GetDTCOfEvent
        GetFaultDetectionCounter: can-be-invoked-concurrently=true, symbol=Dem_GetFaultDetectionCounter
        GetEventFreezeFrameDataEx: can-be-invoked-concurrently=true, symbol=Dem_GetEventFreezeFrameDataEx
        GetEventExtendedDataRecordEx: can-be-invoked-concurrently=true, symbol=Dem_GetEventExtendedDataRecordEx
        GetEventEnableCondition: can-be-invoked-concurrently=true, symbol=Dem_GetEventEnableCondition
        GetDebouncingOfEvent: can-be-invoked-concurrently=true, symbol=Dem_GetDebouncingOfEvent
        GetMonitorStatus: can-be-invoked-concurrently=true, symbol=Dem_GetMonitorStatus
        GetOperationCycleState: can-be-invoked-concurrently=true, symbol=Dem_GetOperationCycleState
        SetOperationCycleState: can-be-invoked-concurrently=true, symbol=Dem_SetOperationCycleState
        GetIndicatorStatus: can-be-invoked-concurrently=true, symbol=Dem_GetIndicatorStatus
        SetEventAvailable: can-be-invoked-concurrently=true, symbol=Dem_SetEventAvailable
        GetEventAvailable: can-be-invoked-concurrently=true, symbol=Dem_GetEventAvailable
  swc implementation DemMaster_Invalid_OsApplicationImplementation: programming-language=C, behavior=DemMaster_Invalid_OsApplicationInternalBehavior
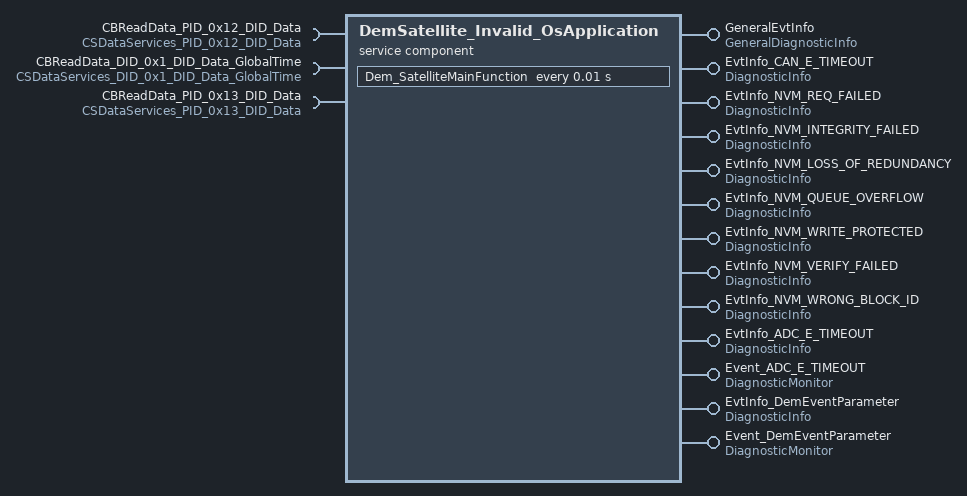
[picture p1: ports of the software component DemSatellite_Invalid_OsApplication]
  service sw component type DemSatellite_Invalid_OsApplication: category=SERVICE_COMPONENT
    provide port GeneralEvtInfo: provided-interface=GeneralDiagnosticInfo
    require port CBReadData_PID_0x12_DID_Data: required-interface=CSDataServices_PID_0x12_DID_Data
    require port CBReadData_DID_0x1_DID_Data_GlobalTime: required-interface=CSDataServices_DID_0x1_DID_Data_GlobalTime
    require port CBReadData_PID_0x13_DID_Data: required-interface=CSDataServices_PID_0x13_DID_Data
    12 x provide port:
      EvtInfo_CAN_E_TIMEOUT: provided-interface=DiagnosticInfo
      EvtInfo_NVM_REQ_FAILED: provided-interface=DiagnosticInfo
      EvtInfo_NVM_INTEGRITY_FAILED: provided-interface=DiagnosticInfo
      EvtInfo_NVM_LOSS_OF_REDUNDANCY: provided-interface=DiagnosticInfo
      EvtInfo_NVM_QUEUE_OVERFLOW: provided-interface=DiagnosticInfo
      EvtInfo_NVM_WRITE_PROTECTED: provided-interface=DiagnosticInfo
      EvtInfo_NVM_VERIFY_FAILED: provided-interface=DiagnosticInfo
      EvtInfo_NVM_WRONG_BLOCK_ID: provided-interface=DiagnosticInfo
      EvtInfo_ADC_E_TIMEOUT: provided-interface=DiagnosticInfo
      Event_ADC_E_TIMEOUT: provided-interface=DiagnosticMonitor
      EvtInfo_DemEventParameter: provided-interface=DiagnosticInfo
      Event_DemEventParameter: provided-interface=DiagnosticMonitor
    behavior DemSatellite_Invalid_OsApplicationInternalBehavior: handle-termination-and-restart=NO-SUPPORT, included-data-type-set=data-type=[Dem_EventIdType, Dem_BufferLengthType, Dcm_NegativeResponseCodeType, Dem_RatioIdType, Dem_EventStatusType, Dem_UdsStatusByteType, Dem_DTCFormatType, Dem_InitMonitorReasonType, Dem_OperationCycleStateType, Dem_DTCStatusMaskType, Dem_IndicatorStatusType, Dem_MaxDataValueType, Dem_DTCKindType, Dem_DTCGroupType, Dem_IumprDenomCondIdType, Dem_IumprDenomCondStatusType, Dem_DebounceResetStatusType, Dem_DebouncingStateType, Dem_IumprReadinessGroupType, Dem_DTRControlType, Dem_DTCSeverityType, Dem_MonitorStatusType]
      timing event Timer_Dem_SatelliteMainFunction: start-on-event=Dem_SatelliteMainFunction, period=0.01
      143 x operation invoked event:
        OpEventGetEventUdsStatus_GetEventUdsStatus_GeneralEvtInfo: start-on-event=DemSatellite_Invalid_OsApplicationInternalBehavior/GetEventUdsStatus, operation=GeneralEvtInfo.GetEventUdsStatus
        OpEventGetEventStatus_GetEventStatus_GeneralEvtInfo: start-on-event=DemSatellite_Invalid_OsApplicationInternalBehavior/GetEventStatus, operation=GeneralEvtInfo.GetEventStatus
        OpEventGetEventFailed_GetEventFailed_GeneralEvtInfo: start-on-event=DemSatellite_Invalid_OsApplicationInternalBehavior/GetEventFailed, operation=GeneralEvtInfo.GetEventFailed
        OpEventGetEventTested_GetEventTested_GeneralEvtInfo: start-on-event=DemSatellite_Invalid_OsApplicationInternalBehavior/GetEventTested, operation=GeneralEvtInfo.GetEventTested
        OpEventGetDTCOfEvent_GetDTCOfEvent_GeneralEvtInfo: start-on-event=DemSatellite_Invalid_OsApplicationInternalBehavior/GetDTCOfEvent, operation=GeneralEvtInfo.GetDTCOfEvent
        OpEventGetFaultDetectionCounter_GetFaultDetectionCounter_GeneralEvtInfo: start-on-event=DemSatellite_Invalid_OsApplicationInternalBehavior/GetFaultDetectionCounter, operation=GeneralEvtInfo.GetFaultDetectionCounter
        OpEventGetEventFreezeFrameDataEx_GetEventFreezeFrameDataEx_GeneralEvtInfo: start-on-event=DemSatellite_Invalid_OsApplicationInternalBehavior/GetEventFreezeFrameDataEx, operation=GeneralEvtInfo.GetEventFreezeFrameDataEx
        OpEventGetEventExtendedDataRecordEx_GetEventExtendedDataRecordEx_GeneralEvtInfo: start-on-event=DemSatellite_Invalid_OsApplicationInternalBehavior/GetEventExtendedDataRecordEx, operation=GeneralEvtInfo.GetEventExtendedDataRecordEx
        OpEventGetEventEnableCondition_GetEventEnableCondition_GeneralEvtInfo: start-on-event=DemSatellite_Invalid_OsApplicationInternalBehavior/GetEventEnableCondition, operation=GeneralEvtInfo.GetEventEnableCondition
        OpEventGetDebouncingOfEvent_GetDebouncingOfEvent_GeneralEvtInfo: start-on-event=DemSatellite_Invalid_OsApplicationInternalBehavior/GetDebouncingOfEvent, operation=GeneralEvtInfo.GetDebouncingOfEvent
        OpEventGetMonitorStatus_GetMonitorStatus_GeneralEvtInfo: start-on-event=DemSatellite_Invalid_OsApplicationInternalBehavior/GetMonitorStatus, operation=GeneralEvtInfo.GetMonitorStatus
        OpEventGetEventUdsStatus_GetEventUdsStatus_EvtInfo_CAN_E_TIMEOUT: start-on-event=DemSatellite_Invalid_OsApplicationInternalBehavior/GetEventUdsStatus, operation=EvtInfo_CAN_E_TIMEOUT.GetEventUdsStatus
        OpEventGetEventUdsStatus_GetEventUdsStatus_EvtInfo_NVM_REQ_FAILED: start-on-event=DemSatellite_Invalid_OsApplicationInternalBehavior/GetEventUdsStatus, operation=EvtInfo_NVM_REQ_FAILED.GetEventUdsStatus
        OpEventGetEventUdsStatus_GetEventUdsStatus_EvtInfo_NVM_INTEGRITY_FAILED: start-on-event=DemSatellite_Invalid_OsApplicationInternalBehavior/GetEventUdsStatus, operation=EvtInfo_NVM_INTEGRITY_FAILED.GetEventUdsStatus
        OpEventGetEventUdsStatus_GetEventUdsStatus_EvtInfo_NVM_LOSS_OF_REDUNDANCY: start-on-event=DemSatellite_Invalid_OsApplicationInternalBehavior/GetEventUdsStatus, operation=EvtInfo_NVM_LOSS_OF_REDUNDANCY.GetEventUdsStatus
        OpEventGetEventUdsStatus_GetEventUdsStatus_EvtInfo_NVM_QUEUE_OVERFLOW: start-on-event=DemSatellite_Invalid_OsApplicationInternalBehavior/GetEventUdsStatus, operation=EvtInfo_NVM_QUEUE_OVERFLOW.GetEventUdsStatus
        OpEventGetEventUdsStatus_GetEventUdsStatus_EvtInfo_NVM_WRITE_PROTECTED: start-on-event=DemSatellite_Invalid_OsApplicationInternalBehavior/GetEventUdsStatus, operation=EvtInfo_NVM_WRITE_PROTECTED.GetEventUdsStatus
        OpEventGetEventUdsStatus_GetEventUdsStatus_EvtInfo_NVM_VERIFY_FAILED: start-on-event=DemSatellite_Invalid_OsApplicationInternalBehavior/GetEventUdsStatus, operation=EvtInfo_NVM_VERIFY_FAILED.GetEventUdsStatus
        OpEventGetEventUdsStatus_GetEventUdsStatus_EvtInfo_NVM_WRONG_BLOCK_ID: start-on-event=DemSatellite_Invalid_OsApplicationInternalBehavior/GetEventUdsStatus, operation=EvtInfo_NVM_WRONG_BLOCK_ID.GetEventUdsStatus
        OpEventGetEventUdsStatus_GetEventUdsStatus_EvtInfo_ADC_E_TIMEOUT: start-on-event=DemSatellite_Invalid_OsApplicationInternalBehavior/GetEventUdsStatus, operation=EvtInfo_ADC_E_TIMEOUT.GetEventUdsStatus
        OpEventGetEventUdsStatus_GetEventUdsStatus_Event_ADC_E_TIMEOUT: start-on-event=DemSatellite_Invalid_OsApplicationInternalBehavior/GetEventUdsStatus, operation=Event_ADC_E_TIMEOUT.GetEventUdsStatus
        OpEventGetEventUdsStatus_GetEventUdsStatus_EvtInfo_DemEventParameter: start-on-event=DemSatellite_Invalid_OsApplicationInternalBehavior/GetEventUdsStatus, operation=EvtInfo_DemEventParameter.GetEventUdsStatus
        OpEventGetEventUdsStatus_GetEventUdsStatus_Event_DemEventParameter: start-on-event=DemSatellite_Invalid_OsApplicationInternalBehavior/GetEventUdsStatus, operation=Event_DemEventParameter.GetEventUdsStatus
        OpEventGetEventStatus_GetEventStatus_EvtInfo_CAN_E_TIMEOUT: start-on-event=DemSatellite_Invalid_OsApplicationInternalBehavior/GetEventStatus, operation=EvtInfo_CAN_E_TIMEOUT.GetEventStatus
        OpEventGetEventStatus_GetEventStatus_EvtInfo_NVM_REQ_FAILED: start-on-event=DemSatellite_Invalid_OsApplicationInternalBehavior/GetEventStatus, operation=EvtInfo_NVM_REQ_FAILED.GetEventStatus
        OpEventGetEventStatus_GetEventStatus_EvtInfo_NVM_INTEGRITY_FAILED: start-on-event=DemSatellite_Invalid_OsApplicationInternalBehavior/GetEventStatus, operation=EvtInfo_NVM_INTEGRITY_FAILED.GetEventStatus
        OpEventGetEventStatus_GetEventStatus_EvtInfo_NVM_LOSS_OF_REDUNDANCY: start-on-event=DemSatellite_Invalid_OsApplicationInternalBehavior/GetEventStatus, operation=EvtInfo_NVM_LOSS_OF_REDUNDANCY.GetEventStatus
        OpEventGetEventStatus_GetEventStatus_EvtInfo_NVM_QUEUE_OVERFLOW: start-on-event=DemSatellite_Invalid_OsApplicationInternalBehavior/GetEventStatus, operation=EvtInfo_NVM_QUEUE_OVERFLOW.GetEventStatus
        OpEventGetEventStatus_GetEventStatus_EvtInfo_NVM_WRITE_PROTECTED: start-on-event=DemSatellite_Invalid_OsApplicationInternalBehavior/GetEventStatus, operation=EvtInfo_NVM_WRITE_PROTECTED.GetEventStatus
        OpEventGetEventStatus_GetEventStatus_EvtInfo_NVM_VERIFY_FAILED: start-on-event=DemSatellite_Invalid_OsApplicationInternalBehavior/GetEventStatus, operation=EvtInfo_NVM_VERIFY_FAILED.GetEventStatus
        OpEventGetEventStatus_GetEventStatus_EvtInfo_NVM_WRONG_BLOCK_ID: start-on-event=DemSatellite_Invalid_OsApplicationInternalBehavior/GetEventStatus, operation=EvtInfo_NVM_WRONG_BLOCK_ID.GetEventStatus
        OpEventGetEventStatus_GetEventStatus_EvtInfo_ADC_E_TIMEOUT: start-on-event=DemSatellite_Invalid_OsApplicationInternalBehavior/GetEventStatus, operation=EvtInfo_ADC_E_TIMEOUT.GetEventStatus
        OpEventGetEventStatus_GetEventStatus_Event_ADC_E_TIMEOUT: start-on-event=DemSatellite_Invalid_OsApplicationInternalBehavior/GetEventStatus, operation=Event_ADC_E_TIMEOUT.GetEventStatus
        OpEventGetEventStatus_GetEventStatus_EvtInfo_DemEventParameter: start-on-event=DemSatellite_Invalid_OsApplicationInternalBehavior/GetEventStatus, operation=EvtInfo_DemEventParameter.GetEventStatus
        OpEventGetEventStatus_GetEventStatus_Event_DemEventParameter: start-on-event=DemSatellite_Invalid_OsApplicationInternalBehavior/GetEventStatus, operation=Event_DemEventParameter.GetEventStatus
        OpEventGetEventFailed_GetEventFailed_EvtInfo_CAN_E_TIMEOUT: start-on-event=DemSatellite_Invalid_OsApplicationInternalBehavior/GetEventFailed, operation=EvtInfo_CAN_E_TIMEOUT.GetEventFailed
        OpEventGetEventFailed_GetEventFailed_EvtInfo_NVM_REQ_FAILED: start-on-event=DemSatellite_Invalid_OsApplicationInternalBehavior/GetEventFailed, operation=EvtInfo_NVM_REQ_FAILED.GetEventFailed
        OpEventGetEventFailed_GetEventFailed_EvtInfo_NVM_INTEGRITY_FAILED: start-on-event=DemSatellite_Invalid_OsApplicationInternalBehavior/GetEventFailed, operation=EvtInfo_NVM_INTEGRITY_FAILED.GetEventFailed
        OpEventGetEventFailed_GetEventFailed_EvtInfo_NVM_LOSS_OF_REDUNDANCY: start-on-event=DemSatellite_Invalid_OsApplicationInternalBehavior/GetEventFailed, operation=EvtInfo_NVM_LOSS_OF_REDUNDANCY.GetEventFailed
        OpEventGetEventFailed_GetEventFailed_EvtInfo_NVM_QUEUE_OVERFLOW: start-on-event=DemSatellite_Invalid_OsApplicationInternalBehavior/GetEventFailed, operation=EvtInfo_NVM_QUEUE_OVERFLOW.GetEventFailed
        OpEventGetEventFailed_GetEventFailed_EvtInfo_NVM_WRITE_PROTECTED: start-on-event=DemSatellite_Invalid_OsApplicationInternalBehavior/GetEventFailed, operation=EvtInfo_NVM_WRITE_PROTECTED.GetEventFailed
        OpEventGetEventFailed_GetEventFailed_EvtInfo_NVM_VERIFY_FAILED: start-on-event=DemSatellite_Invalid_OsApplicationInternalBehavior/GetEventFailed, operation=EvtInfo_NVM_VERIFY_FAILED.GetEventFailed
        OpEventGetEventFailed_GetEventFailed_EvtInfo_NVM_WRONG_BLOCK_ID: start-on-event=DemSatellite_Invalid_OsApplicationInternalBehavior/GetEventFailed, operation=EvtInfo_NVM_WRONG_BLOCK_ID.GetEventFailed
        OpEventGetEventFailed_GetEventFailed_EvtInfo_ADC_E_TIMEOUT: start-on-event=DemSatellite_Invalid_OsApplicationInternalBehavior/GetEventFailed, operation=EvtInfo_ADC_E_TIMEOUT.GetEventFailed
        OpEventGetEventFailed_GetEventFailed_Event_ADC_E_TIMEOUT: start-on-event=DemSatellite_Invalid_OsApplicationInternalBehavior/GetEventFailed, operation=Event_ADC_E_TIMEOUT.GetEventFailed
        OpEventGetEventFailed_GetEventFailed_EvtInfo_DemEventParameter: start-on-event=DemSatellite_Invalid_OsApplicationInternalBehavior/GetEventFailed, operation=EvtInfo_DemEventParameter.GetEventFailed
        OpEventGetEventFailed_GetEventFailed_Event_DemEventParameter: start-on-event=DemSatellite_Invalid_OsApplicationInternalBehavior/GetEventFailed, operation=Event_DemEventParameter.GetEventFailed
        OpEventGetEventTested_GetEventTested_EvtInfo_CAN_E_TIMEOUT: start-on-event=DemSatellite_Invalid_OsApplicationInternalBehavior/GetEventTested, operation=EvtInfo_CAN_E_TIMEOUT.GetEventTested
        OpEventGetEventTested_GetEventTested_EvtInfo_NVM_REQ_FAILED: start-on-event=DemSatellite_Invalid_OsApplicationInternalBehavior/GetEventTested, operation=EvtInfo_NVM_REQ_FAILED.GetEventTested
        OpEventGetEventTested_GetEventTested_EvtInfo_NVM_INTEGRITY_FAILED: start-on-event=DemSatellite_Invalid_OsApplicationInternalBehavior/GetEventTested, operation=EvtInfo_NVM_INTEGRITY_FAILED.GetEventTested
        OpEventGetEventTested_GetEventTested_EvtInfo_NVM_LOSS_OF_REDUNDANCY: start-on-event=DemSatellite_Invalid_OsApplicationInternalBehavior/GetEventTested, operation=EvtInfo_NVM_LOSS_OF_REDUNDANCY.GetEventTested
        OpEventGetEventTested_GetEventTested_EvtInfo_NVM_QUEUE_OVERFLOW: start-on-event=DemSatellite_Invalid_OsApplicationInternalBehavior/GetEventTested, operation=EvtInfo_NVM_QUEUE_OVERFLOW.GetEventTested
        OpEventGetEventTested_GetEventTested_EvtInfo_NVM_WRITE_PROTECTED: start-on-event=DemSatellite_Invalid_OsApplicationInternalBehavior/GetEventTested, operation=EvtInfo_NVM_WRITE_PROTECTED.GetEventTested
        OpEventGetEventTested_GetEventTested_EvtInfo_NVM_VERIFY_FAILED: start-on-event=DemSatellite_Invalid_OsApplicationInternalBehavior/GetEventTested, operation=EvtInfo_NVM_VERIFY_FAILED.GetEventTested
        OpEventGetEventTested_GetEventTested_EvtInfo_NVM_WRONG_BLOCK_ID: start-on-event=DemSatellite_Invalid_OsApplicationInternalBehavior/GetEventTested, operation=EvtInfo_NVM_WRONG_BLOCK_ID.GetEventTested
        OpEventGetEventTested_GetEventTested_EvtInfo_ADC_E_TIMEOUT: start-on-event=DemSatellite_Invalid_OsApplicationInternalBehavior/GetEventTested, operation=EvtInfo_ADC_E_TIMEOUT.GetEventTested
        OpEventGetEventTested_GetEventTested_Event_ADC_E_TIMEOUT: start-on-event=DemSatellite_Invalid_OsApplicationInternalBehavior/GetEventTested, operation=Event_ADC_E_TIMEOUT.GetEventTested
        OpEventGetEventTested_GetEventTested_EvtInfo_DemEventParameter: start-on-event=DemSatellite_Invalid_OsApplicationInternalBehavior/GetEventTested, operation=EvtInfo_DemEventParameter.GetEventTested
        OpEventGetEventTested_GetEventTested_Event_DemEventParameter: start-on-event=DemSatellite_Invalid_OsApplicationInternalBehavior/GetEventTested, operation=Event_DemEventParameter.GetEventTested
        OpEventGetDTCOfEvent_GetDTCOfEvent_EvtInfo_CAN_E_TIMEOUT: start-on-event=DemSatellite_Invalid_OsApplicationInternalBehavior/GetDTCOfEvent, operation=EvtInfo_CAN_E_TIMEOUT.GetDTCOfEvent
        OpEventGetDTCOfEvent_GetDTCOfEvent_EvtInfo_NVM_REQ_FAILED: start-on-event=DemSatellite_Invalid_OsApplicationInternalBehavior/GetDTCOfEvent, operation=EvtInfo_NVM_REQ_FAILED.GetDTCOfEvent
        OpEventGetDTCOfEvent_GetDTCOfEvent_EvtInfo_NVM_INTEGRITY_FAILED: start-on-event=DemSatellite_Invalid_OsApplicationInternalBehavior/GetDTCOfEvent, operation=EvtInfo_NVM_INTEGRITY_FAILED.GetDTCOfEvent
        OpEventGetDTCOfEvent_GetDTCOfEvent_EvtInfo_NVM_LOSS_OF_REDUNDANCY: start-on-event=DemSatellite_Invalid_OsApplicationInternalBehavior/GetDTCOfEvent, operation=EvtInfo_NVM_LOSS_OF_REDUNDANCY.GetDTCOfEvent
        OpEventGetDTCOfEvent_GetDTCOfEvent_EvtInfo_NVM_QUEUE_OVERFLOW: start-on-event=DemSatellite_Invalid_OsApplicationInternalBehavior/GetDTCOfEvent, operation=EvtInfo_NVM_QUEUE_OVERFLOW.GetDTCOfEvent
        OpEventGetDTCOfEvent_GetDTCOfEvent_EvtInfo_NVM_WRITE_PROTECTED: start-on-event=DemSatellite_Invalid_OsApplicationInternalBehavior/GetDTCOfEvent, operation=EvtInfo_NVM_WRITE_PROTECTED.GetDTCOfEvent
        OpEventGetDTCOfEvent_GetDTCOfEvent_EvtInfo_NVM_VERIFY_FAILED: start-on-event=DemSatellite_Invalid_OsApplicationInternalBehavior/GetDTCOfEvent, operation=EvtInfo_NVM_VERIFY_FAILED.GetDTCOfEvent
        OpEventGetDTCOfEvent_GetDTCOfEvent_EvtInfo_NVM_WRONG_BLOCK_ID: start-on-event=DemSatellite_Invalid_OsApplicationInternalBehavior/GetDTCOfEvent, operation=EvtInfo_NVM_WRONG_BLOCK_ID.GetDTCOfEvent
        OpEventGetDTCOfEvent_GetDTCOfEvent_EvtInfo_ADC_E_TIMEOUT: start-on-event=DemSatellite_Invalid_OsApplicationInternalBehavior/GetDTCOfEvent, operation=EvtInfo_ADC_E_TIMEOUT.GetDTCOfEvent
        OpEventGetDTCOfEvent_GetDTCOfEvent_Event_ADC_E_TIMEOUT: start-on-event=DemSatellite_Invalid_OsApplicationInternalBehavior/GetDTCOfEvent, operation=Event_ADC_E_TIMEOUT.GetDTCOfEvent
        OpEventGetDTCOfEvent_GetDTCOfEvent_EvtInfo_DemEventParameter: start-on-event=DemSatellite_Invalid_OsApplicationInternalBehavior/GetDTCOfEvent, operation=EvtInfo_DemEventParameter.GetDTCOfEvent
        OpEventGetDTCOfEvent_GetDTCOfEvent_Event_DemEventParameter: start-on-event=DemSatellite_Invalid_OsApplicationInternalBehavior/GetDTCOfEvent, operation=Event_DemEventParameter.GetDTCOfEvent
        OpEventGetFaultDetectionCounter_GetFaultDetectionCounter_EvtInfo_CAN_E_TIMEOUT: start-on-event=DemSatellite_Invalid_OsApplicationInternalBehavior/GetFaultDetectionCounter, operation=EvtInfo_CAN_E_TIMEOUT.GetFaultDetectionCounter
        OpEventGetFaultDetectionCounter_GetFaultDetectionCounter_EvtInfo_NVM_REQ_FAILED: start-on-event=DemSatellite_Invalid_OsApplicationInternalBehavior/GetFaultDetectionCounter, operation=EvtInfo_NVM_REQ_FAILED.GetFaultDetectionCounter
        OpEventGetFaultDetectionCounter_GetFaultDetectionCounter_EvtInfo_NVM_INTEGRITY_FAILED: start-on-event=DemSatellite_Invalid_OsApplicationInternalBehavior/GetFaultDetectionCounter, operation=EvtInfo_NVM_INTEGRITY_FAILED.GetFaultDetectionCounter
        OpEventGetFaultDetectionCounter_GetFaultDetectionCounter_EvtInfo_NVM_LOSS_OF_REDUNDANCY: start-on-event=DemSatellite_Invalid_OsApplicationInternalBehavior/GetFaultDetectionCounter, operation=EvtInfo_NVM_LOSS_OF_REDUNDANCY.GetFaultDetectionCounter
        OpEventGetFaultDetectionCounter_GetFaultDetectionCounter_EvtInfo_NVM_QUEUE_OVERFLOW: start-on-event=DemSatellite_Invalid_OsApplicationInternalBehavior/GetFaultDetectionCounter, operation=EvtInfo_NVM_QUEUE_OVERFLOW.GetFaultDetectionCounter
        OpEventGetFaultDetectionCounter_GetFaultDetectionCounter_EvtInfo_NVM_WRITE_PROTECTED: start-on-event=DemSatellite_Invalid_OsApplicationInternalBehavior/GetFaultDetectionCounter, operation=EvtInfo_NVM_WRITE_PROTECTED.GetFaultDetectionCounter
        OpEventGetFaultDetectionCounter_GetFaultDetectionCounter_EvtInfo_NVM_VERIFY_FAILED: start-on-event=DemSatellite_Invalid_OsApplicationInternalBehavior/GetFaultDetectionCounter, operation=EvtInfo_NVM_VERIFY_FAILED.GetFaultDetectionCounter
        OpEventGetFaultDetectionCounter_GetFaultDetectionCounter_EvtInfo_NVM_WRONG_BLOCK_ID: start-on-event=DemSatellite_Invalid_OsApplicationInternalBehavior/GetFaultDetectionCounter, operation=EvtInfo_NVM_WRONG_BLOCK_ID.GetFaultDetectionCounter
        OpEventGetFaultDetectionCounter_GetFaultDetectionCounter_EvtInfo_ADC_E_TIMEOUT: start-on-event=DemSatellite_Invalid_OsApplicationInternalBehavior/GetFaultDetectionCounter, operation=EvtInfo_ADC_E_TIMEOUT.GetFaultDetectionCounter
        OpEventGetFaultDetectionCounter_GetFaultDetectionCounter_Event_ADC_E_TIMEOUT: start-on-event=DemSatellite_Invalid_OsApplicationInternalBehavior/GetFaultDetectionCounter, operation=Event_ADC_E_TIMEOUT.GetFaultDetectionCounter
        OpEventGetFaultDetectionCounter_GetFaultDetectionCounter_EvtInfo_DemEventParameter: start-on-event=DemSatellite_Invalid_OsApplicationInternalBehavior/GetFaultDetectionCounter, operation=EvtInfo_DemEventParameter.GetFaultDetectionCounter
        OpEventGetFaultDetectionCounter_GetFaultDetectionCounter_Event_DemEventParameter: start-on-event=DemSatellite_Invalid_OsApplicationInternalBehavior/GetFaultDetectionCounter, operation=Event_DemEventParameter.GetFaultDetectionCounter
        OpEventGetEventFreezeFrameDataEx_GetEventFreezeFrameDataEx_EvtInfo_CAN_E_TIMEOUT: start-on-event=DemSatellite_Invalid_OsApplicationInternalBehavior/GetEventFreezeFrameDataEx, operation=EvtInfo_CAN_E_TIMEOUT.GetEventFreezeFrameDataEx
        OpEventGetEventFreezeFrameDataEx_GetEventFreezeFrameDataEx_EvtInfo_NVM_REQ_FAILED: start-on-event=DemSatellite_Invalid_OsApplicationInternalBehavior/GetEventFreezeFrameDataEx, operation=EvtInfo_NVM_REQ_FAILED.GetEventFreezeFrameDataEx
        OpEventGetEventFreezeFrameDataEx_GetEventFreezeFrameDataEx_EvtInfo_NVM_INTEGRITY_FAILED: start-on-event=DemSatellite_Invalid_OsApplicationInternalBehavior/GetEventFreezeFrameDataEx, operation=EvtInfo_NVM_INTEGRITY_FAILED.GetEventFreezeFrameDataEx
        OpEventGetEventFreezeFrameDataEx_GetEventFreezeFrameDataEx_EvtInfo_NVM_LOSS_OF_REDUNDANCY: start-on-event=DemSatellite_Invalid_OsApplicationInternalBehavior/GetEventFreezeFrameDataEx, operation=EvtInfo_NVM_LOSS_OF_REDUNDANCY.GetEventFreezeFrameDataEx
        OpEventGetEventFreezeFrameDataEx_GetEventFreezeFrameDataEx_EvtInfo_NVM_QUEUE_OVERFLOW: start-on-event=DemSatellite_Invalid_OsApplicationInternalBehavior/GetEventFreezeFrameDataEx, operation=EvtInfo_NVM_QUEUE_OVERFLOW.GetEventFreezeFrameDataEx
        OpEventGetEventFreezeFrameDataEx_GetEventFreezeFrameDataEx_EvtInfo_NVM_WRITE_PROTECTED: start-on-event=DemSatellite_Invalid_OsApplicationInternalBehavior/GetEventFreezeFrameDataEx, operation=EvtInfo_NVM_WRITE_PROTECTED.GetEventFreezeFrameDataEx
        OpEventGetEventFreezeFrameDataEx_GetEventFreezeFrameDataEx_EvtInfo_NVM_VERIFY_FAILED: start-on-event=DemSatellite_Invalid_OsApplicationInternalBehavior/GetEventFreezeFrameDataEx, operation=EvtInfo_NVM_VERIFY_FAILED.GetEventFreezeFrameDataEx
        OpEventGetEventFreezeFrameDataEx_GetEventFreezeFrameDataEx_EvtInfo_NVM_WRONG_BLOCK_ID: start-on-event=DemSatellite_Invalid_OsApplicationInternalBehavior/GetEventFreezeFrameDataEx, operation=EvtInfo_NVM_WRONG_BLOCK_ID.GetEventFreezeFrameDataEx
        OpEventGetEventFreezeFrameDataEx_GetEventFreezeFrameDataEx_EvtInfo_ADC_E_TIMEOUT: start-on-event=DemSatellite_Invalid_OsApplicationInternalBehavior/GetEventFreezeFrameDataEx, operation=EvtInfo_ADC_E_TIMEOUT.GetEventFreezeFrameDataEx
        OpEventGetEventFreezeFrameDataEx_GetEventFreezeFrameDataEx_Event_ADC_E_TIMEOUT: start-on-event=DemSatellite_Invalid_OsApplicationInternalBehavior/GetEventFreezeFrameDataEx, operation=Event_ADC_E_TIMEOUT.GetEventFreezeFrameDataEx
        OpEventGetEventFreezeFrameDataEx_GetEventFreezeFrameDataEx_EvtInfo_DemEventParameter: start-on-event=DemSatellite_Invalid_OsApplicationInternalBehavior/GetEventFreezeFrameDataEx, operation=EvtInfo_DemEventParameter.GetEventFreezeFrameDataEx
        OpEventGetEventFreezeFrameDataEx_GetEventFreezeFrameDataEx_Event_DemEventParameter: start-on-event=DemSatellite_Invalid_OsApplicationInternalBehavior/GetEventFreezeFrameDataEx, operation=Event_DemEventParameter.GetEventFreezeFrameDataEx
        OpEventGetEventExtendedDataRecordEx_GetEventExtendedDataRecordEx_EvtInfo_CAN_E_TIMEOUT: start-on-event=DemSatellite_Invalid_OsApplicationInternalBehavior/GetEventExtendedDataRecordEx, operation=EvtInfo_CAN_E_TIMEOUT.GetEventExtendedDataRecordEx
        OpEventGetEventExtendedDataRecordEx_GetEventExtendedDataRecordEx_EvtInfo_NVM_REQ_FAILED: start-on-event=DemSatellite_Invalid_OsApplicationInternalBehavior/GetEventExtendedDataRecordEx, operation=EvtInfo_NVM_REQ_FAILED.GetEventExtendedDataRecordEx
        OpEventGetEventExtendedDataRecordEx_GetEventExtendedDataRecordEx_EvtInfo_NVM_INTEGRITY_FAILED: start-on-event=DemSatellite_Invalid_OsApplicationInternalBehavior/GetEventExtendedDataRecordEx, operation=EvtInfo_NVM_INTEGRITY_FAILED.GetEventExtendedDataRecordEx
        OpEventGetEventExtendedDataRecordEx_GetEventExtendedDataRecordEx_EvtInfo_NVM_LOSS_OF_REDUNDANCY: start-on-event=DemSatellite_Invalid_OsApplicationInternalBehavior/GetEventExtendedDataRecordEx, operation=EvtInfo_NVM_LOSS_OF_REDUNDANCY.GetEventExtendedDataRecordEx
        OpEventGetEventExtendedDataRecordEx_GetEventExtendedDataRecordEx_EvtInfo_NVM_QUEUE_OVERFLOW: start-on-event=DemSatellite_Invalid_OsApplicationInternalBehavior/GetEventExtendedDataRecordEx, operation=EvtInfo_NVM_QUEUE_OVERFLOW.GetEventExtendedDataRecordEx
        OpEventGetEventExtendedDataRecordEx_GetEventExtendedDataRecordEx_EvtInfo_NVM_WRITE_PROTECTED: start-on-event=DemSatellite_Invalid_OsApplicationInternalBehavior/GetEventExtendedDataRecordEx, operation=EvtInfo_NVM_WRITE_PROTECTED.GetEventExtendedDataRecordEx
        OpEventGetEventExtendedDataRecordEx_GetEventExtendedDataRecordEx_EvtInfo_NVM_VERIFY_FAILED: start-on-event=DemSatellite_Invalid_OsApplicationInternalBehavior/GetEventExtendedDataRecordEx, operation=EvtInfo_NVM_VERIFY_FAILED.GetEventExtendedDataRecordEx
        OpEventGetEventExtendedDataRecordEx_GetEventExtendedDataRecordEx_EvtInfo_NVM_WRONG_BLOCK_ID: start-on-event=DemSatellite_Invalid_OsApplicationInternalBehavior/GetEventExtendedDataRecordEx, operation=EvtInfo_NVM_WRONG_BLOCK_ID.GetEventExtendedDataRecordEx
        OpEventGetEventExtendedDataRecordEx_GetEventExtendedDataRecordEx_EvtInfo_ADC_E_TIMEOUT: start-on-event=DemSatellite_Invalid_OsApplicationInternalBehavior/GetEventExtendedDataRecordEx, operation=EvtInfo_ADC_E_TIMEOUT.GetEventExtendedDataRecordEx
        OpEventGetEventExtendedDataRecordEx_GetEventExtendedDataRecordEx_Event_ADC_E_TIMEOUT: start-on-event=DemSatellite_Invalid_OsApplicationInternalBehavior/GetEventExtendedDataRecordEx, operation=Event_ADC_E_TIMEOUT.GetEventExtendedDataRecordEx
        OpEventGetEventExtendedDataRecordEx_GetEventExtendedDataRecordEx_EvtInfo_DemEventParameter: start-on-event=DemSatellite_Invalid_OsApplicationInternalBehavior/GetEventExtendedDataRecordEx, operation=EvtInfo_DemEventParameter.GetEventExtendedDataRecordEx
        OpEventGetEventExtendedDataRecordEx_GetEventExtendedDataRecordEx_Event_DemEventParameter: start-on-event=DemSatellite_Invalid_OsApplicationInternalBehavior/GetEventExtendedDataRecordEx, operation=Event_DemEventParameter.GetEventExtendedDataRecordEx
        OpEventGetEventEnableCondition_GetEventEnableCondition_EvtInfo_CAN_E_TIMEOUT: start-on-event=DemSatellite_Invalid_OsApplicationInternalBehavior/GetEventEnableCondition, operation=EvtInfo_CAN_E_TIMEOUT.GetEventEnableCondition
        OpEventGetEventEnableCondition_GetEventEnableCondition_EvtInfo_NVM_REQ_FAILED: start-on-event=DemSatellite_Invalid_OsApplicationInternalBehavior/GetEventEnableCondition, operation=EvtInfo_NVM_REQ_FAILED.GetEventEnableCondition
        OpEventGetEventEnableCondition_GetEventEnableCondition_EvtInfo_NVM_INTEGRITY_FAILED: start-on-event=DemSatellite_Invalid_OsApplicationInternalBehavior/GetEventEnableCondition, operation=EvtInfo_NVM_INTEGRITY_FAILED.GetEventEnableCondition
        OpEventGetEventEnableCondition_GetEventEnableCondition_EvtInfo_NVM_LOSS_OF_REDUNDANCY: start-on-event=DemSatellite_Invalid_OsApplicationInternalBehavior/GetEventEnableCondition, operation=EvtInfo_NVM_LOSS_OF_REDUNDANCY.GetEventEnableCondition
        OpEventGetEventEnableCondition_GetEventEnableCondition_EvtInfo_NVM_QUEUE_OVERFLOW: start-on-event=DemSatellite_Invalid_OsApplicationInternalBehavior/GetEventEnableCondition, operation=EvtInfo_NVM_QUEUE_OVERFLOW.GetEventEnableCondition
        OpEventGetEventEnableCondition_GetEventEnableCondition_EvtInfo_NVM_WRITE_PROTECTED: start-on-event=DemSatellite_Invalid_OsApplicationInternalBehavior/GetEventEnableCondition, operation=EvtInfo_NVM_WRITE_PROTECTED.GetEventEnableCondition
        OpEventGetEventEnableCondition_GetEventEnableCondition_EvtInfo_NVM_VERIFY_FAILED: start-on-event=DemSatellite_Invalid_OsApplicationInternalBehavior/GetEventEnableCondition, operation=EvtInfo_NVM_VERIFY_FAILED.GetEventEnableCondition
        OpEventGetEventEnableCondition_GetEventEnableCondition_EvtInfo_NVM_WRONG_BLOCK_ID: start-on-event=DemSatellite_Invalid_OsApplicationInternalBehavior/GetEventEnableCondition, operation=EvtInfo_NVM_WRONG_BLOCK_ID.GetEventEnableCondition
        OpEventGetEventEnableCondition_GetEventEnableCondition_EvtInfo_ADC_E_TIMEOUT: start-on-event=DemSatellite_Invalid_OsApplicationInternalBehavior/GetEventEnableCondition, operation=EvtInfo_ADC_E_TIMEOUT.GetEventEnableCondition
        OpEventGetEventEnableCondition_GetEventEnableCondition_EvtInfo_DemEventParameter: start-on-event=DemSatellite_Invalid_OsApplicationInternalBehavior/GetEventEnableCondition, operation=EvtInfo_DemEventParameter.GetEventEnableCondition
        OpEventGetDebouncingOfEvent_GetDebouncingOfEvent_EvtInfo_CAN_E_TIMEOUT: start-on-event=DemSatellite_Invalid_OsApplicationInternalBehavior/GetDebouncingOfEvent, operation=EvtInfo_CAN_E_TIMEOUT.GetDebouncingOfEvent
        OpEventGetDebouncingOfEvent_GetDebouncingOfEvent_EvtInfo_NVM_REQ_FAILED: start-on-event=DemSatellite_Invalid_OsApplicationInternalBehavior/GetDebouncingOfEvent, operation=EvtInfo_NVM_REQ_FAILED.GetDebouncingOfEvent
        OpEventGetDebouncingOfEvent_GetDebouncingOfEvent_EvtInfo_NVM_INTEGRITY_FAILED: start-on-event=DemSatellite_Invalid_OsApplicationInternalBehavior/GetDebouncingOfEvent, operation=EvtInfo_NVM_INTEGRITY_FAILED.GetDebouncingOfEvent
        OpEventGetDebouncingOfEvent_GetDebouncingOfEvent_EvtInfo_NVM_LOSS_OF_REDUNDANCY: start-on-event=DemSatellite_Invalid_OsApplicationInternalBehavior/GetDebouncingOfEvent, operation=EvtInfo_NVM_LOSS_OF_REDUNDANCY.GetDebouncingOfEvent
        OpEventGetDebouncingOfEvent_GetDebouncingOfEvent_EvtInfo_NVM_QUEUE_OVERFLOW: start-on-event=DemSatellite_Invalid_OsApplicationInternalBehavior/GetDebouncingOfEvent, operation=EvtInfo_NVM_QUEUE_OVERFLOW.GetDebouncingOfEvent
        OpEventGetDebouncingOfEvent_GetDebouncingOfEvent_EvtInfo_NVM_WRITE_PROTECTED: start-on-event=DemSatellite_Invalid_OsApplicationInternalBehavior/GetDebouncingOfEvent, operation=EvtInfo_NVM_WRITE_PROTECTED.GetDebouncingOfEvent
        OpEventGetDebouncingOfEvent_GetDebouncingOfEvent_EvtInfo_NVM_VERIFY_FAILED: start-on-event=DemSatellite_Invalid_OsApplicationInternalBehavior/GetDebouncingOfEvent, operation=EvtInfo_NVM_VERIFY_FAILED.GetDebouncingOfEvent
        OpEventGetDebouncingOfEvent_GetDebouncingOfEvent_EvtInfo_NVM_WRONG_BLOCK_ID: start-on-event=DemSatellite_Invalid_OsApplicationInternalBehavior/GetDebouncingOfEvent, operation=EvtInfo_NVM_WRONG_BLOCK_ID.GetDebouncingOfEvent
        OpEventGetDebouncingOfEvent_GetDebouncingOfEvent_EvtInfo_ADC_E_TIMEOUT: start-on-event=DemSatellite_Invalid_OsApplicationInternalBehavior/GetDebouncingOfEvent, operation=EvtInfo_ADC_E_TIMEOUT.GetDebouncingOfEvent
        OpEventGetDebouncingOfEvent_GetDebouncingOfEvent_EvtInfo_DemEventParameter: start-on-event=DemSatellite_Invalid_OsApplicationInternalBehavior/GetDebouncingOfEvent, operation=EvtInfo_DemEventParameter.GetDebouncingOfEvent
        OpEventGetMonitorStatus_GetMonitorStatus_EvtInfo_CAN_E_TIMEOUT: start-on-event=DemSatellite_Invalid_OsApplicationInternalBehavior/GetMonitorStatus, operation=EvtInfo_CAN_E_TIMEOUT.GetMonitorStatus
        OpEventGetMonitorStatus_GetMonitorStatus_EvtInfo_NVM_REQ_FAILED: start-on-event=DemSatellite_Invalid_OsApplicationInternalBehavior/GetMonitorStatus, operation=EvtInfo_NVM_REQ_FAILED.GetMonitorStatus
        OpEventGetMonitorStatus_GetMonitorStatus_EvtInfo_NVM_INTEGRITY_FAILED: start-on-event=DemSatellite_Invalid_OsApplicationInternalBehavior/GetMonitorStatus, operation=EvtInfo_NVM_INTEGRITY_FAILED.GetMonitorStatus
        OpEventGetMonitorStatus_GetMonitorStatus_EvtInfo_NVM_LOSS_OF_REDUNDANCY: start-on-event=DemSatellite_Invalid_OsApplicationInternalBehavior/GetMonitorStatus, operation=EvtInfo_NVM_LOSS_OF_REDUNDANCY.GetMonitorStatus
        OpEventGetMonitorStatus_GetMonitorStatus_EvtInfo_NVM_QUEUE_OVERFLOW: start-on-event=DemSatellite_Invalid_OsApplicationInternalBehavior/GetMonitorStatus, operation=EvtInfo_NVM_QUEUE_OVERFLOW.GetMonitorStatus
        OpEventGetMonitorStatus_GetMonitorStatus_EvtInfo_NVM_WRITE_PROTECTED: start-on-event=DemSatellite_Invalid_OsApplicationInternalBehavior/GetMonitorStatus, operation=EvtInfo_NVM_WRITE_PROTECTED.GetMonitorStatus
        OpEventGetMonitorStatus_GetMonitorStatus_EvtInfo_NVM_VERIFY_FAILED: start-on-event=DemSatellite_Invalid_OsApplicationInternalBehavior/GetMonitorStatus, operation=EvtInfo_NVM_VERIFY_FAILED.GetMonitorStatus
        OpEventGetMonitorStatus_GetMonitorStatus_EvtInfo_NVM_WRONG_BLOCK_ID: start-on-event=DemSatellite_Invalid_OsApplicationInternalBehavior/GetMonitorStatus, operation=EvtInfo_NVM_WRONG_BLOCK_ID.GetMonitorStatus
        OpEventGetMonitorStatus_GetMonitorStatus_EvtInfo_ADC_E_TIMEOUT: start-on-event=DemSatellite_Invalid_OsApplicationInternalBehavior/GetMonitorStatus, operation=EvtInfo_ADC_E_TIMEOUT.GetMonitorStatus
        OpEventGetMonitorStatus_GetMonitorStatus_EvtInfo_DemEventParameter: start-on-event=DemSatellite_Invalid_OsApplicationInternalBehavior/GetMonitorStatus, operation=EvtInfo_DemEventParameter.GetMonitorStatus
        OpEventSetEventStatus_SetEventStatus_Event_ADC_E_TIMEOUT: start-on-event=SetEventStatus, operation=Event_ADC_E_TIMEOUT.SetEventStatus
        OpEventSetEventStatus_SetEventStatus_Event_DemEventParameter: start-on-event=SetEventStatus, operation=Event_DemEventParameter.SetEventStatus
        OpEventResetEventStatus_ResetEventStatus_Event_ADC_E_TIMEOUT: start-on-event=ResetEventStatus, operation=Event_ADC_E_TIMEOUT.ResetEventStatus
        OpEventResetEventStatus_ResetEventStatus_Event_DemEventParameter: start-on-event=ResetEventStatus, operation=Event_DemEventParameter.ResetEventStatus
        OpEventResetEventDebounceStatus_ResetEventDebounceStatus_Event_ADC_E_TIMEOUT: start-on-event=ResetEventDebounceStatus, operation=Event_ADC_E_TIMEOUT.ResetEventDebounceStatus
        OpEventResetEventDebounceStatus_ResetEventDebounceStatus_Event_DemEventParameter: start-on-event=ResetEventDebounceStatus, operation=Event_DemEventParameter.ResetEventDebounceStatus
      port-api-options:
        enable-take-address=true, indirect-api=false, port=DemSatellite_Invalid_OsApplication/GeneralEvtInfo
        enable-take-address=true, indirect-api=false, port=DemSatellite_Invalid_OsApplication/CBReadData_PID_0x12_DID_Data
        enable-take-address=true, indirect-api=false, port=DemSatellite_Invalid_OsApplication/CBReadData_DID_0x1_DID_Data_GlobalTime
        enable-take-address=true, indirect-api=false, port=DemSatellite_Invalid_OsApplication/CBReadData_PID_0x13_DID_Data
        {enable-take-address=true, indirect-api=false, port-defined-argument-value{value=1, value-type=Dem_EventIdType}, port=EvtInfo_CAN_E_TIMEOUT}
        {enable-take-address=true, indirect-api=false, port-defined-argument-value{value=5, value-type=Dem_EventIdType}, port=EvtInfo_NVM_REQ_FAILED}
        {enable-take-address=true, indirect-api=false, port-defined-argument-value{value=2, value-type=Dem_EventIdType}, port=EvtInfo_NVM_INTEGRITY_FAILED}
        {enable-take-address=true, indirect-api=false, port-defined-argument-value{value=3, value-type=Dem_EventIdType}, port=EvtInfo_NVM_LOSS_OF_REDUNDANCY}
        {enable-take-address=true, indirect-api=false, port-defined-argument-value{value=4, value-type=Dem_EventIdType}, port=EvtInfo_NVM_QUEUE_OVERFLOW}
        {enable-take-address=true, indirect-api=false, port-defined-argument-value{value=7, value-type=Dem_EventIdType}, port=EvtInfo_NVM_WRITE_PROTECTED}
        {enable-take-address=true, indirect-api=false, port-defined-argument-value{value=6, value-type=Dem_EventIdType}, port=EvtInfo_NVM_VERIFY_FAILED}
        {enable-take-address=true, indirect-api=false, port-defined-argument-value{value=8, value-type=Dem_EventIdType}, port=EvtInfo_NVM_WRONG_BLOCK_ID}
        {enable-take-address=true, indirect-api=false, port-defined-argument-value{value=9, value-type=Dem_EventIdType}, port=EvtInfo_ADC_E_TIMEOUT}
        {enable-take-address=true, indirect-api=false, port-defined-argument-value{value=9, value-type=Dem_EventIdType}, port=Event_ADC_E_TIMEOUT}
        {enable-take-address=true, indirect-api=false, port-defined-argument-value{value=10, value-type=Dem_EventIdType}, port=EvtInfo_DemEventParameter}
        {enable-take-address=true, indirect-api=false, port-defined-argument-value{value=10, value-type=Dem_EventIdType}, port=Event_DemEventParameter}
      15 x runnable:
        Dem_SatelliteMainFunction
          sync call OpServerCallDem_SatelliteMainFunction_ReadData_CBReadData_PID_0x12_DID_Data: operation=CBReadData_PID_0x12_DID_Data.ReadData, timeout=0
          sync call OpServerCallDem_SatelliteMainFunction_ReadData_CBReadData_DID_0x1_DID_Data_GlobalTime: operation=CBReadData_DID_0x1_DID_Data_GlobalTime.ReadData, timeout=0
          sync call OpServerCallDem_SatelliteMainFunction_ReadData_CBReadData_PID_0x13_DID_Data: operation=CBReadData_PID_0x13_DID_Data.ReadData, timeout=0
        GetEventUdsStatus: can-be-invoked-concurrently=true, symbol=Dem_GetEventUdsStatus
        GetEventStatus: can-be-invoked-concurrently=true, symbol=Dem_GetEventUdsStatus
        GetEventFailed: can-be-invoked-concurrently=true, symbol=Dem_GetEventFailed
        GetEventTested: can-be-invoked-concurrently=true, symbol=Dem_GetEventTested
        GetDTCOfEvent: can-be-invoked-concurrently=true, symbol=Dem_GetDTCOfEvent
        GetFaultDetectionCounter: can-be-invoked-concurrently=true, symbol=Dem_GetFaultDetectionCounter
        GetEventFreezeFrameDataEx: can-be-invoked-concurrently=true, symbol=Dem_GetEventFreezeFrameDataEx
        GetEventExtendedDataRecordEx: can-be-invoked-concurrently=true, symbol=Dem_GetEventExtendedDataRecordEx
        GetEventEnableCondition: can-be-invoked-concurrently=true, symbol=Dem_GetEventEnableCondition
        GetDebouncingOfEvent: can-be-invoked-concurrently=true, symbol=Dem_GetDebouncingOfEvent
        GetMonitorStatus: can-be-invoked-concurrently=true, symbol=Dem_GetMonitorStatus
        SetEventStatus: can-be-invoked-concurrently=true, symbol=Dem_SetEventStatus
        ResetEventStatus: can-be-invoked-concurrently=true, symbol=Dem_ResetEventStatus
        ResetEventDebounceStatus: can-be-invoked-concurrently=true, symbol=Dem_ResetEventDebounceStatus
  swc implementation DemSatellite_Invalid_OsApplicationImplementation: programming-language=C, behavior=DemSatellite_Invalid_OsApplicationInternalBehavior
